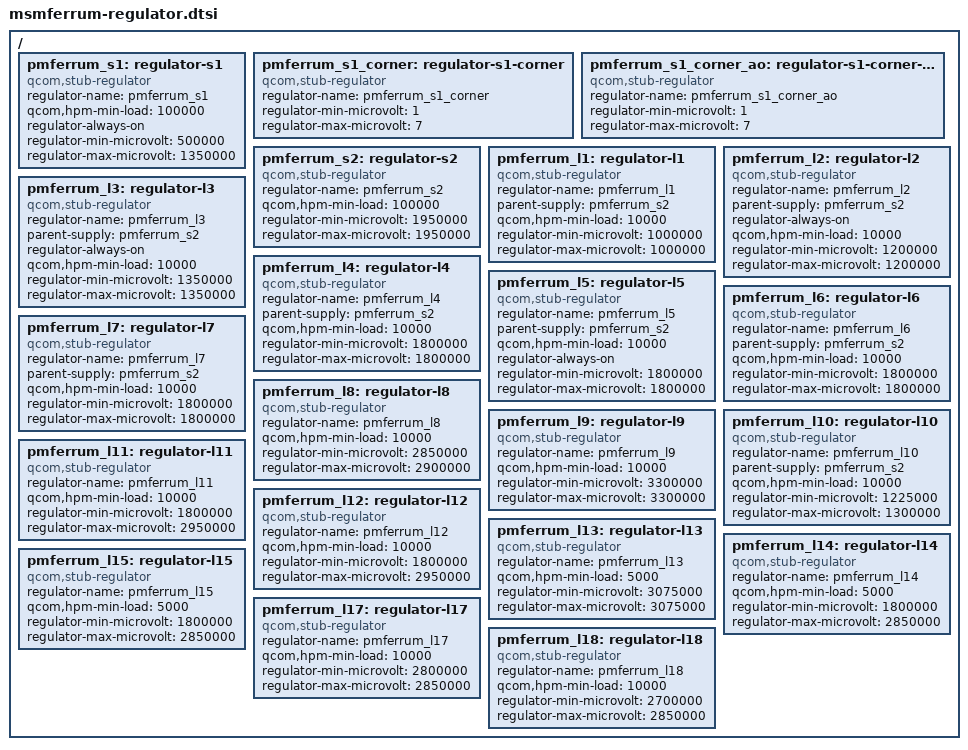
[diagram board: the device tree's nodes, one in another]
/* Copyright (c) 2014, The Linux Foundation. All rights reserved.
 *
 * This program is free software; you can redistribute it and/or modify
 * it under the terms of the GNU General Public License version 2 and
 * only version 2 as published by the Free Software Foundation.
 *
 * This program is distributed in the hope that it will be useful,
 * but WITHOUT ANY WARRANTY; without even the implied warranty of
 * MERCHANTABILITY or FITNESS FOR A PARTICULAR PURPOSE.  See the
 * GNU General Public License for more details.
 */

/* Stub regulators */

/ {
	pmferrum_s1: regulator-s1 {
		compatible = "qcom,stub-regulator";
		regulator-name = "pmferrum_s1";
		qcom,hpm-min-load = <100000>;
		regulator-always-on;
		regulator-min-microvolt = <500000>;
		regulator-max-microvolt = <1350000>;
	};

	pmferrum_s1_corner: regulator-s1-corner {
		compatible = "qcom,stub-regulator";
		regulator-name = "pmferrum_s1_corner";
		regulator-min-microvolt = <1>;
		regulator-max-microvolt = <7>;
	};

	pmferrum_s1_corner_ao: regulator-s1-corner-ao {
		compatible = "qcom,stub-regulator";
		regulator-name = "pmferrum_s1_corner_ao";
		regulator-min-microvolt = <1>;
		regulator-max-microvolt = <7>;
	};


	pmferrum_s2: regulator-s2 {
		compatible = "qcom,stub-regulator";
		regulator-name = "pmferrum_s2";
		qcom,hpm-min-load = <100000>;
		regulator-min-microvolt = <1950000>;
		regulator-max-microvolt = <1950000>;
	};

	pmferrum_l1: regulator-l1 {
		compatible = "qcom,stub-regulator";
		regulator-name = "pmferrum_l1";
		parent-supply = <&pmferrum_s2>;
		qcom,hpm-min-load = <10000>;
		regulator-min-microvolt = <1000000>;
		regulator-max-microvolt = <1000000>;
	};

	pmferrum_l2: regulator-l2 {
		compatible = "qcom,stub-regulator";
		regulator-name = "pmferrum_l2";
		parent-supply = <&pmferrum_s2>;
		regulator-always-on;
		qcom,hpm-min-load = <10000>;
		regulator-min-microvolt = <1200000>;
		regulator-max-microvolt = <1200000>;
	};

	pmferrum_l3: regulator-l3 {
		compatible = "qcom,stub-regulator";
		regulator-name = "pmferrum_l3";
		parent-supply = <&pmferrum_s2>;
		regulator-always-on;
		qcom,hpm-min-load = <10000>;
		regulator-min-microvolt = <1350000>;
		regulator-max-microvolt = <1350000>;
	};

	pmferrum_l4: regulator-l4 {
		compatible = "qcom,stub-regulator";
		regulator-name = "pmferrum_l4";
		parent-supply = <&pmferrum_s2>;
		qcom,hpm-min-load = <10000>;
		regulator-min-microvolt = <1800000>;
		regulator-max-microvolt = <1800000>;
	};

	pmferrum_l5: regulator-l5 {
		compatible = "qcom,stub-regulator";
		regulator-name = "pmferrum_l5";
		parent-supply = <&pmferrum_s2>;
		qcom,hpm-min-load = <10000>;
		regulator-always-on;
		regulator-min-microvolt = <1800000>;
		regulator-max-microvolt = <1800000>;
	};

	pmferrum_l6: regulator-l6 {
		compatible = "qcom,stub-regulator";
		regulator-name = "pmferrum_l6";
		parent-supply = <&pmferrum_s2>;
		qcom,hpm-min-load = <10000>;
		regulator-min-microvolt = <1800000>;
		regulator-max-microvolt = <1800000>;
	};

	pmferrum_l7: regulator-l7 {
		compatible = "qcom,stub-regulator";
		regulator-name = "pmferrum_l7";
		parent-supply = <&pmferrum_s2>;
		qcom,hpm-min-load = <10000>;
		regulator-min-microvolt = <1800000>;
		regulator-max-microvolt = <1800000>;
	};

	pmferrum_l8: regulator-l8 {
		compatible = "qcom,stub-regulator";
		regulator-name = "pmferrum_l8";
		qcom,hpm-min-load = <10000>;
		regulator-min-microvolt = <2850000>;
		regulator-max-microvolt = <2900000>;
	};

	pmferrum_l9: regulator-l9 {
		compatible = "qcom,stub-regulator";
		regulator-name = "pmferrum_l9";
		qcom,hpm-min-load = <10000>;
		regulator-min-microvolt = <3300000>;
		regulator-max-microvolt = <3300000>;
	};

	pmferrum_l10: regulator-l10 {
		compatible = "qcom,stub-regulator";
		regulator-name = "pmferrum_l10";
		parent-supply = <&pmferrum_s2>;
		qcom,hpm-min-load = <10000>;
		regulator-min-microvolt = <1225000>;
		regulator-max-microvolt = <1300000>;
	};

	pmferrum_l11: regulator-l11 {
		compatible = "qcom,stub-regulator";
		regulator-name = "pmferrum_l11";
		qcom,hpm-min-load = <10000>;
		regulator-min-microvolt = <1800000>;
		regulator-max-microvolt = <2950000>;
	};

	pmferrum_l12: regulator-l12 {
		compatible = "qcom,stub-regulator";
		regulator-name = "pmferrum_l12";
		qcom,hpm-min-load = <10000>;
		regulator-min-microvolt = <1800000>;
		regulator-max-microvolt = <2950000>;
	};

	pmferrum_l13: regulator-l13 {
		compatible = "qcom,stub-regulator";
		regulator-name = "pmferrum_l13";
		qcom,hpm-min-load = <5000>;
		regulator-min-microvolt = <3075000>;
		regulator-max-microvolt = <3075000>;
	};

	pmferrum_l14: regulator-l14 {
		compatible = "qcom,stub-regulator";
		regulator-name = "pmferrum_l14";
		qcom,hpm-min-load = <5000>;
		regulator-min-microvolt = <1800000>;
		regulator-max-microvolt = <2850000>;
	};

	pmferrum_l15: regulator-l15 {
		compatible = "qcom,stub-regulator";
		regulator-name = "pmferrum_l15";
		qcom,hpm-min-load = <5000>;
		regulator-min-microvolt = <1800000>;
		regulator-max-microvolt = <2850000>;
	};

	pmferrum_l17: regulator-l17 {
		compatible = "qcom,stub-regulator";
		regulator-name = "pmferrum_l17";
		qcom,hpm-min-load = <10000>;
		regulator-min-microvolt = <2800000>;
		regulator-max-microvolt = <2850000>;
	};

	pmferrum_l18: regulator-l18 {
		compatible = "qcom,stub-regulator";
		regulator-name = "pmferrum_l18";
		qcom,hpm-min-load = <10000>;
		regulator-min-microvolt = <2700000>;
		regulator-max-microvolt = <2850000>;
	};

};
